# STM32MP13xx register map
File version: 1.5
CPU: CA7 r0p0, little endian, MPU, FPU, 4 interrupt priority bits
Registers are 32-bit, read-write, reset 0x0 unless marked. A register's access mark holds for its fields unless they carry their own. Offsets are from the block's base; [hi:lo] are bit positions; {n}, {i} and the like mark numbered series.

## DBGMCU — Microcontroller Debug Unit
Base 0x50081000
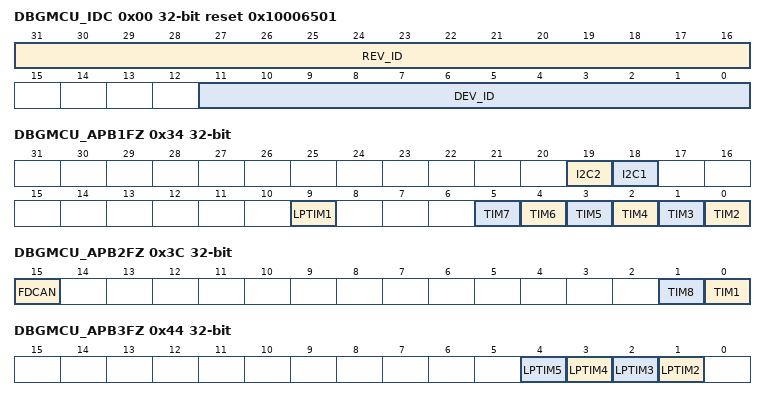
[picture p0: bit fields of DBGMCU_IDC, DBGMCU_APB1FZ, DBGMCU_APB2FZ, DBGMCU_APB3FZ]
0x00 DBGMCU_IDC ro reset 0x10006501 — DBGMCU identity code register
  [31:16] REV_ID — revision 0x1000 = Rev. 1
  [11:0] DEV_ID — device ID
    0x501=STM32MP13xx
0x04 DBGMCU_CR — DBGMCU configuration register
  [2] DBGLP — Low power mode debug enable
    0=normal operation. In Stop, LP-Stop, LPLV-Stop, LPLV-Stop2 and Standby mode, debug access is lost.; 1=automatic clock stop/power down disabled. All active clocks and oscillators continue to run during low power mode, and the VDDCORE and VDDCPU supplies are maintained, allowing full debug capability. On exit from Standby or LPLV-Stop2 modes, the CortexÂ®-A7 is reset.
0x2C DBGMCU_APB4FZ — DBGMCU APB4 peripheral freeze register
  [2] IWDG2 — IWDG2 stop in debug
    0=normal operation. IWDG2 continues to operate while CortexÂ®-A7 is in debug mode.; 1=stop in debug. IWDG2 is frozen while CortexÂ®-A7 core is in debug mode. No accesses are allowed on its APB interface.
0x34 DBGMCU_APB1FZ — DBGMCU APB1 peripheral freeze register
  [19] I2C2 — I2C2 SMBUS timeout stop in debug
    0=normal operation. I2C2 SMBUS timeout continues to operate while CortexÂ®-A7 is in debug mode.; 1=stop in debug. I2C2 SMBUS timeout is frozen while the CortexÂ®-A7 core is in debug mode.
  [18] I2C1 — I2C1 SMBUS timeout stop in debug
    0=normal operation. I2C1 SMBUS timeout continues to operate while CortexÂ®-A7 is in debug mode.; 1=stop in debug. I2C1 SMBUS timeout is frozen while the CortexÂ®-A7 core is in debug mode.
  [9] LPTIM1 — LPTIM1 stop in debug
    0=normal operation. LPTIM1 continues to operate while CortexÂ®-A7 is in debug mode.; 1=stop in debug. LPTIM1 is frozen while the CortexÂ®-A7 core is in debug mode.
  [n-2] TIM{n} (n=3..7) — TIM{n} stop in debug
    0=normal operation. TIM{n} continues to operate while CortexÂ®-A7 is in debug mode.; 1=stop in debug. TIM{n} is frozen while the CortexÂ®-A7 core is in debug mode.
  [0] TIM2 — TIM2 stop in debug
    0=Normal operation. TIM2 continues to operate while CortexÂ®-A7 is in debug mode.; 1=Stop in debug. TIM2 is frozen while the CortexÂ®-A7 core is in debug mode.
0x3C DBGMCU_APB2FZ — DBGMCU APB2 peripheral freeze register
  [15] FDCAN — FDCAN stop in debug
    0=normal operation. FDCAN continues to operate while CortexÂ®-A7 is in debug mode.; 1=stop in debug. FDCAN is frozen while CortexÂ®-A7 core is in debug mode.
  [1] TIM8 — TIM8 stop in debug
    0=normal operation. TIM8 continues to operate while CortexÂ®-A7 is in debug mode.; 1=stop in debug. TIM8 is frozen while the CortexÂ®-A7 core is in debug mode.
  [0] TIM1 — TIM1 stop in debug
    0=normal operation. TIM1 continues to operate while CortexÂ®-A7 is in debug mode.; 1=stop in debug. TIM1 is frozen while the CortexÂ®-A7 core is in debug mode.
0x44 DBGMCU_APB3FZ — DBGMCU APB3 peripheral freeze register
  [n-1] LPTIM{n} (n=2..5) — LPTIM{n} stop in debug
    0=normal operation. LPTIM{n} continues to operate while CortexÂ®-A7 is in debug mode.; 1=stop in debug. LPTIM{n} is frozen while the CortexÂ®-A7 core is in debug mode.
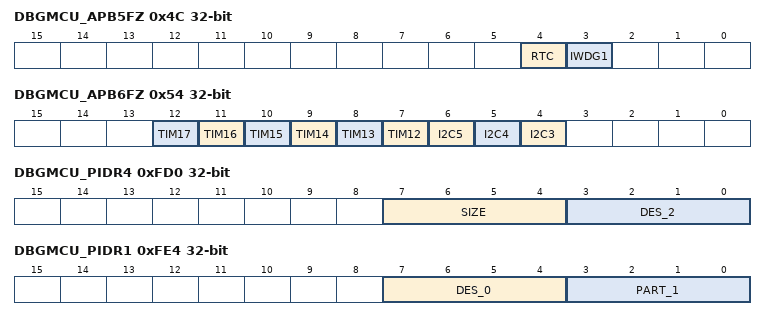
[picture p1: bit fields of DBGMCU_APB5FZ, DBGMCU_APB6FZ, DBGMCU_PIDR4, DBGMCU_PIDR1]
0x4C DBGMCU_APB5FZ — DBGMCU APB5 peripheral freeze register
  [4] RTC — RTC stop in debug
    0=normal operation. RTC continues to operate while CortexÂ®-A7 is in debug mode.; 1=stop in debug. RTC is frozen while the CortexÂ®-A7 core is in debug mode.
  [3] IWDG1 — independent watchdog 1 stop in debug
    0=normal operation. Watchdog continues to count while CortexÂ®-A7 is in debug mode.; 1=stop in debug. IWGD1 is frozen while the CortexÂ®-A7 core is in debug mode. No accesses are allowed on its APB interface.
0x54 DBGMCU_APB6FZ — DBGMCU APB6 peripheral freeze register
  [n-5] TIM{n} (n=12..17) — TIM{n} stop in debug
    0=normal operation. TIM{n} continues to operate while CortexÂ®-A7 is in debug mode.; 1=stop in debug. TIM{n} is frozen while CortexÂ®-A7 is in debug mode.
  [6] I2C5 — I2C5 SMBUS stop in debug
    0=normal operation. I2C5 SMBUS timeout continues to operate while CortexÂ®-A7 is in debug mode.; 1=stop in debug. I2C5 SMBUS timeout is frozen while CortexÂ®-A7 is in debug mode.
  [5] I2C4 — I2C4 SMBUS stop in debug
    0=normal operation. I2C4 SMBUS timeout continues to operate while CortexÂ®-A7 is in debug mode.; 1=stop in debug. I2C4 SMBUS timeout is frozen while CortexÂ®-A7 is in debug mode.
  [4] I2C3 — I2C3 SMBUS stop in debug
    0=normal operation. I2C3 SMBUS timeout continues to operate while CortexÂ®-A7 is in debug mode.; 1=stop in debug. I2C3 SMBUS timeout is frozen while CortexÂ®-A7 is in debug mode.
0xFD0 DBGMCU_PIDR4 ro — DBGMCU peripheral ID4 register
  [7:4] SIZE — component memory size indicator Indicates the total contiguous size of the memory window used by the component in powers of two from the standard 4Â Kbytes. If a component only requires the standard 4Â Kbytes, this bit field must read as 0x0. For 8Â Kbytes it is set to 0x1. For 16Â Kbytes it set to 0x2. For 32Â Kbytes it is set to 0x3, and similarly for larger memory windows.
    0=the device only occupies 4 Kbytes of memory
  [3:0] DES_2 — JEDEC continuation code Indicates the designer of the component, together with the identity code.
    0=indicates that STMicroelectronics JEDEC identity code is on the 1st bank
0xFE0 DBGMCU_PIDR0 ro — DBGMCU peripheral ID0 register
  [7:0] PART_0 — bits [7:0] of the component part number This field is specified by the designer of the component.
    0=CoreSightâ¢ DBGMCU Part Number[7:0]. Eight least significant bits of the part number (0x000).
0xFE4 DBGMCU_PIDR1 ro — DBGMCU peripheral ID1 register
  [7:4] DES_0 — bits [3:0] of the JEDEC identity code Indicates the designer of the component, together with the continuation code.
    0=least significant four bits of the JEP106 identity code (0x20 = STMicroelectronics)
  [3:0] PART_1 — bits [11:8] of the component part number Specified by the designer of the component.
    0=CoreSightâ¢ DBGMCU part number[11:8]. Most significant four bits of the part number (0x000).
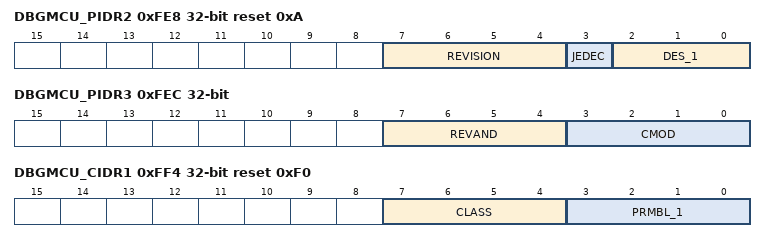
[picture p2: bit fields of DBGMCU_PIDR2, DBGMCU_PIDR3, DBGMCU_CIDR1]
0xFE8 DBGMCU_PIDR2 ro reset 0xA — DBGMCU peripheral ID2 register
  [7:4] REVISION — incremental component design version An incremental value starting from 0x0 for the first design of this component. The value increases by one at both major and minor revisions and is used as a look-up to establish the exact major and minor revisions.
    0=this component is at rev0
  [3] JEDEC — JEDEC assigned value usage Indicates the use of a JEDEC assigned value. This bit is always set.
    1=the designer ID is specified by JEDEC (refer to http://www.jedec.org)
  [2:0] DES_1 — bits [6:4] of the JEDEC identity code Indicates the designer of the component, together with the continuation code.
    2=most significant three bits of the JEP106 identity code (0x20 = STMicroelectronics)
0xFEC DBGMCU_PIDR3 ro — DBGMCU peripheral ID3 register
  [7:4] REVAND — minor fix indicator Indicates minor errata fixes specific to the design, for example metal fixes after implementation. In most cases this field is 0x0. ArmÂ® recommends that the component designers ensure that the bit field can be changed by a metal fix if required, for example by driving the bit field from registers that reset to zero.
    0=no metal fix in the component
  [3:0] CMOD — customer modification indicator When the component is a reusable IP, this value indicates if the customer has modified the behavior of the component. In most cases this field is 0x0.
    0=no modification made
0xFF0 DBGMCU_CIDR0 ro reset 0xD — DBGMCU component ID0 register
  [7:0] PRMBL_0 — bits [31:24] of component identification Component identification register, that indicates that the identification registers are present.
    13=identification value
0xFF4 DBGMCU_CIDR1 ro reset 0xF0 — DBGMCU component ID1 register
  [7:4] CLASS — component class Indicates the class of the component, for example, ROM table or CoreSightâ¢ component.
    15=indicates that the component is a non-CoreSightâ¢ component
  [3:0] PRMBL_1 — bits [19:16] of component identification. Component identification register, that indicates that the identification registers are present.
    0=identification value
0xFF8 DBGMCU_CIDR2 ro reset 0x5 — DBGMCU component ID2 register
  [7:0] PRMBL_2 — bits [15:8] of component identification Component identification register, that indicates that the identification registers are present.
    5=identification value
0xFFC DBGMCU_CIDR3 ro reset 0xB1 — DBGMCU component ID3 register
  [7:0] PRMBL_3 — bits [7:0] of component identification Component identification register, that indicates that the identification registers are present.
    177=identification value
